AUTOSAR XML (schema 00048)
package /VehicleProject
  system System
package /Cluster
  can cluster CAN00: protocol-name=CAN  # CANFD364
    can physical channel CHNL: comm-connectors=CN_CAN00
      frame msg_MyECU_Lamp_oCAN00: id 0x511, from MyECU, frame-length=32, can-addressing-mode=STANDARD, can-frame-rx-behavior=ANY, can-frame-tx-behavior=CAN-FD
        pdu msg_MyECU_Lamp_oCAN00: length=32, minimum-delay=0, transmission-mode-false-timing=cyclic-timing={time-offset=0, time-period=0.1}, transmission-mode-true-timing=cyclic-timing={time-offset=0, time-period=0.1}, unused-bit-pattern=0
          signal sig_LampCnt_omsg_MyECU_Lamp_oCAN00: start 7, 8 bit, big-endian, i-signal-type=PRIMITIVE, init-value=0, base-type=uint8, compu-method=CM_sig_LampCnt, data-constr=DC_sig_LampCnt, transfer-property=PENDING
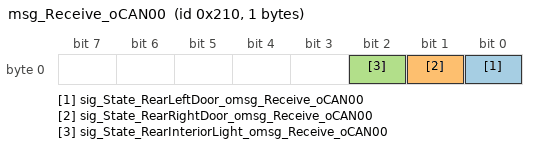
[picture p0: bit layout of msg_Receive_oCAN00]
      frame msg_Receive_oCAN00: id 0x210, to MyECU, frame-length=1, can-addressing-mode=STANDARD, can-frame-rx-behavior=ANY, can-frame-tx-behavior=CAN-20
        pdu msg_Receive_oCAN00: length=1, minimum-delay=0, transmission-mode-false-timing=cyclic-timing={time-offset=0, time-period=0.1}, transmission-mode-true-timing=cyclic-timing={time-offset=0, time-period=0.1}, unused-bit-pattern=0
          signal sig_State_RearLeftDoor_omsg_Receive_oCAN00: start 0, 1 bit, little-endian, i-signal-type=PRIMITIVE, init-value=0, base-type=boolean, compu-method=CM_sig_State_RearLeftDoor, data-constr=DC_sig_State_RearLeftDoor, transfer-property=PENDING, to MyECU
          signal sig_State_RearRightDoor_omsg_Receive_oCAN00: start 1, 1 bit, little-endian, i-signal-type=PRIMITIVE, init-value=0, base-type=boolean, compu-method=CM_sig_State_RearRightDoor, data-constr=DC_sig_State_RearRightDoor, transfer-property=PENDING, to MyECU
          signal sig_State_RearInteriorLight_omsg_Receive_oCAN00: start 2, 1 bit, little-endian, i-signal-type=PRIMITIVE, init-value=0, base-type=boolean, compu-method=CM_sig_State_RearInteriorLight, data-constr=DC_sig_State_RearInteriorLight, transfer-property=PENDING, to MyECU
      frame msg_Transmit_oCAN00: id 0x200, from MyECU, frame-length=1, can-addressing-mode=STANDARD, can-frame-rx-behavior=ANY, can-frame-tx-behavior=CAN-20
        pdu msg_Transmit_oCAN00: length=1, minimum-delay=0, transmission-mode-false-timing=cyclic-timing={time-offset=0, time-period=0.1}, transmission-mode-true-timing=cyclic-timing={time-offset=0, time-period=0.1}, unused-bit-pattern=0
          signal sig_RearInteriorLight_omsg_Transmit_oCAN00: start 0, 1 bit, little-endian, i-signal-type=PRIMITIVE, init-value=0, base-type=boolean, compu-method=CM_sig_RearInteriorLight, data-constr=DC_sig_RearInteriorLight, transfer-property=PENDING
package /ECU
  ecu instance MyECU: associated-com-i-pdu-group=[MyECU_oCAN00_Rx, MyECU_oCAN00_Tx]
    can communication controller CT_CAN00
    can communication connector CN_CAN00: comm-controller=CT_CAN00
package /IPDUGroup
  i signal i pdu group MyECU_oCAN00_Rx: communication-direction=IN, i-signal-i-pdus=msg_Receive_oCAN00
  i signal i pdu group MyECU_oCAN00_Tx: communication-direction=OUT, i-signal-i-pdus=[msg_MyECU_Lamp_oCAN00, msg_Transmit_oCAN00]
